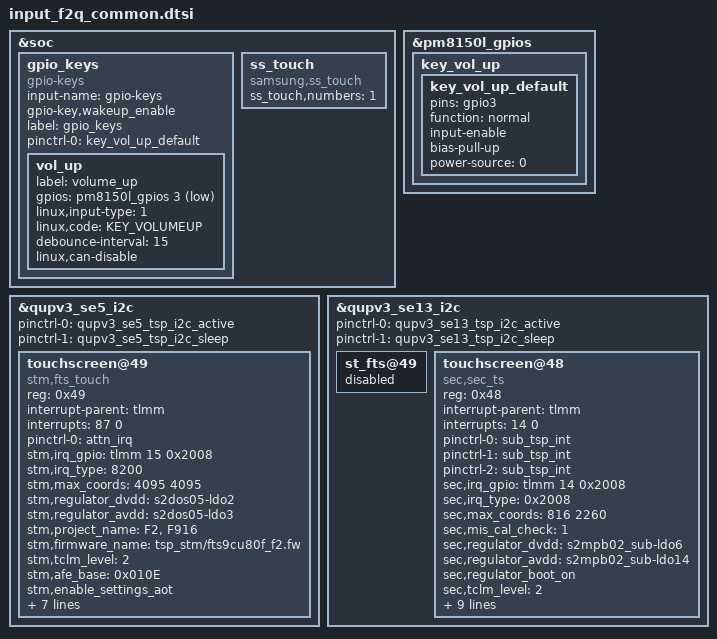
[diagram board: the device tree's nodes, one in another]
/* Copyright (c) 2016-2017, The Linux Foundation. All rights reserved.
 *
 * This program is free software; you can redistribute it and/or modify
 * it under the terms of the GNU General Public License version 2 and
 * only version 2 as published by the Free Software Foundation.
 *
 * This program is distributed in the hope that it will be useful,
 * but WITHOUT ANY WARRANTY; without even the implied warranty of
 * MERCHANTABILITY or FITNESS FOR A PARTICULAR PURPOSE.  See the
 * GNU General Public License for more details.
 */

#include <dt-bindings/input/input.h>

/delete-node/ &gpio_keys;
&soc {
	gpio_keys: gpio_keys {
		status = "ok";
		compatible = "gpio-keys";
		input-name = "gpio-keys";
		gpio-key,wakeup_enable;
		label = "gpio_keys";

		pinctrl-names = "default";
		pinctrl-0 = <&key_vol_up_default>;

		vol_up {
			label = "volume_up";
			gpios = <&pm8150l_gpios 3 GPIO_ACTIVE_LOW>;
			linux,input-type = <1>;
			linux,code = <KEY_VOLUMEUP>;
			debounce-interval = <15>;
			linux,can-disable;
		};
	};

	ss_touch {
		compatible = "samsung,ss_touch";
		ss_touch,numbers = <1>;
	};
};

/delete-node/ &key_vol_up_default;

&pm8150l_gpios {
	key_vol_up {
		key_vol_up_default: key_vol_up_default {
			pins = "gpio3";
			function = "normal";
			input-enable;
			bias-pull-up;
			power-source = <0>;
		};
	};
};

/* tsp power, regulator-boot-on setting : kona-sec-f2q-r04.dtsi */

&qupv3_se5_i2c {
	pinctrl-0 = <&qupv3_se5_tsp_i2c_active>;
	pinctrl-1 = <&qupv3_se5_tsp_i2c_sleep>;
	status = "ok";

	/* stm */
	touchscreen@49 {
		status = "ok";
		compatible = "stm,fts_touch";
		reg = <0x49>;
		interrupt-parent = <&tlmm>;
		interrupts = <87 0>;
		pinctrl-names = "default";
		pinctrl-0 = <&attn_irq>;
		stm,irq_gpio = <&tlmm 15 0x2008>;
		stm,irq_type = <8200>;
		stm,max_coords = <4095 4095>;	/* x y */
		stm,regulator_dvdd = "s2dos05-ldo2";
		stm,regulator_avdd = "s2dos05-ldo3";
		stm,project_name = "F2", "F916";
		stm,firmware_name = "tsp_stm/fts9cu80f_f2.fw";
		stm,tclm_level = <2>;
		stm,afe_base = <0x010E>;
		stm,enable_settings_aot;
		support_dex_mode;
		stm,ss_touch_num = <1>;
/*		sync-reportrate-120 = "Y";*/
		support_open_short_test;
		support_mis_calibration_test;
		support_sram_test;
		support_hall_ic;
		support_flex_mode;
	};
};

&qupv3_se13_i2c {
	pinctrl-0 = <&qupv3_se13_tsp_i2c_active>;
	pinctrl-1 = <&qupv3_se13_tsp_i2c_sleep>;
	status = "ok";

	st_fts@49 {
		status = "disabled";
	};

	touchscreen@48 {
		status = "ok";
		compatible = "sec,sec_ts";
		reg = <0x48>;
		interrupt-parent = <&tlmm>;
		interrupts = <14 0>;
		pinctrl-names = "default", "on_state", "off_state";
		pinctrl-0 = <&sub_tsp_int>;
		pinctrl-1 = <&sub_tsp_int>;
		pinctrl-2 = <&sub_tsp_int>;
		sec,irq_gpio = <&tlmm 14 0x2008>;
		sec,irq_type = <0x2008>;
		sec,max_coords = <816 2260>; /* x y */
		sec,mis_cal_check = <1>;
		sec,regulator_dvdd = "s2mpb02_sub-ldo6";
		sec,regulator_avdd = "s2mpb02_sub-ldo14";
		sec,regulator_boot_on;
/*		sec,always_lpmode = <1>;*/
		sec,tclm_level = <2>;
		sec,afe_base = <0x0108>;
		sec,firmware_name = "tsp_sec/y771_f2.bin";
		sec,i2c-burstmax = <0x01000000>;
		sec,factory_item_version = <2>;
		sec,ss_touch_num = <2>;
		support_open_short_test;
		support_mis_calibration_test;
		support_dex_mode;
		support_ear_detect_mode;
	};
};
